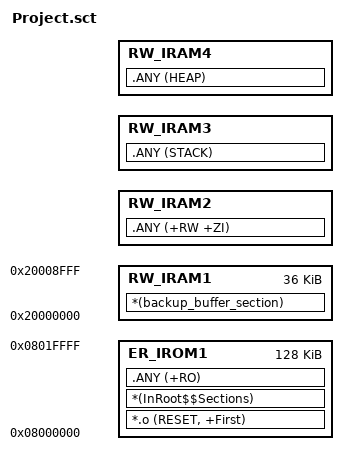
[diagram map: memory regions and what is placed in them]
; *************************************************************
; *** Scatter-Loading Description File generated by uVision ***
; *************************************************************

LR_IROM1 0x08000000 0x00020000  {    ; load region size_region
  ER_IROM1 0x08000000 0x00020000  {  ; load address = execution address
   *.o (RESET, +First)
   *(InRoot$$Sections)
   .ANY (+RO)
  }
  RW_IRAM1 0x20000000 0x00009000  {  ; RW data
  *(backup_buffer_section)
  }
  RW_IRAM2 +0  {  ; RW data
  .ANY (+RW +ZI)
  } 
  
  RW_IRAM3 +0  {  ; RW data
  .ANY (STACK)
  }
  RW_IRAM4 +0  {  ; RW data
  .ANY (HEAP)
  }
}

